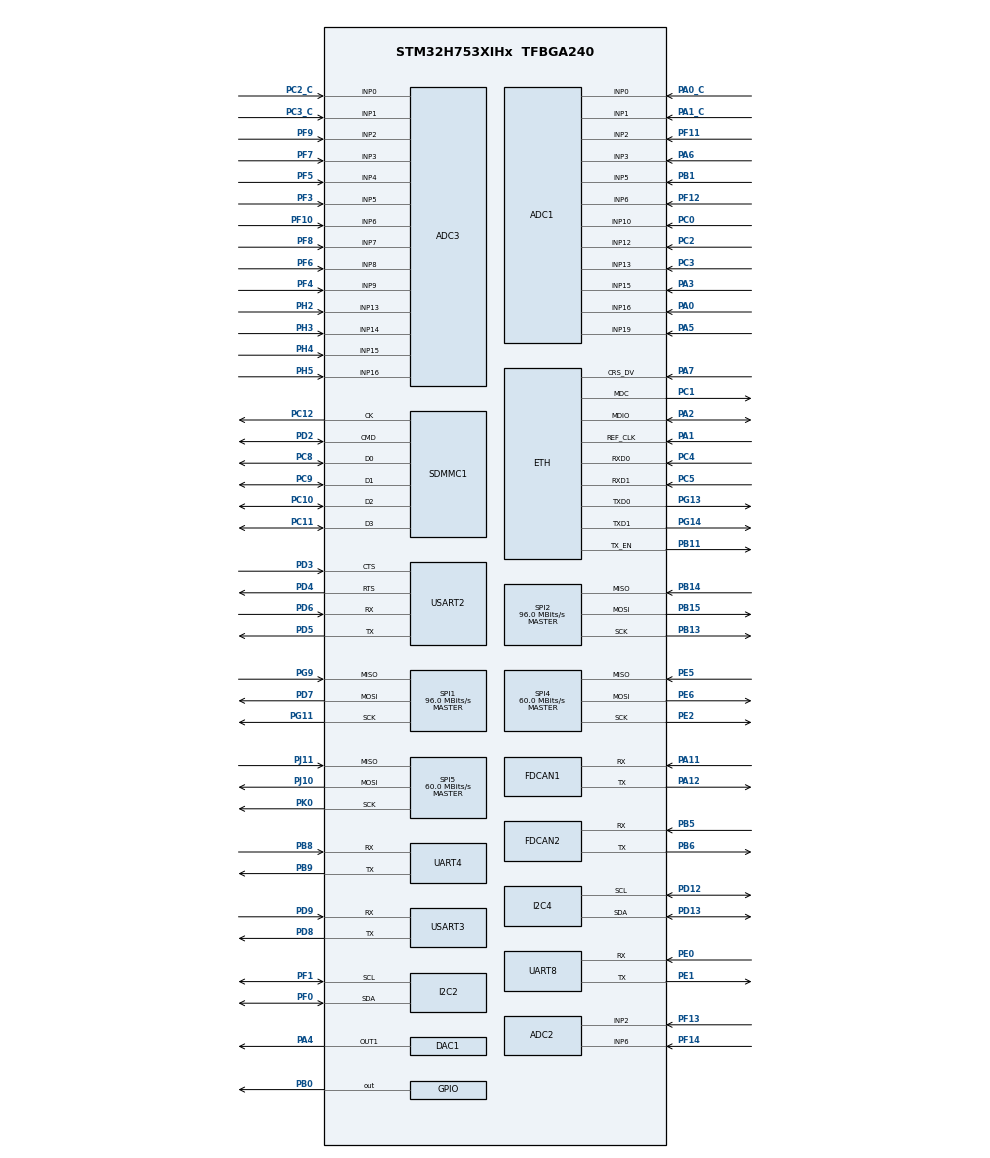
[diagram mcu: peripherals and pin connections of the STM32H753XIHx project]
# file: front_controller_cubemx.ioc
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ADC1.Channel-0\#ChannelRegularConversion=ADC_CHANNEL_1
ADC1.NbrOfConversionFlag=1
ADC1.OffsetNumber-0\#ChannelRegularConversion=ADC_OFFSET_NONE
ADC1.OffsetSignedSaturation-0\#ChannelRegularConversion=DISABLE
ADC1.Rank-0\#ChannelRegularConversion=1
ADC1.SamplingTime-0\#ChannelRegularConversion=ADC_SAMPLETIME_1CYCLE_5
ADC1.master=1
ADC2.Channel-1\#ChannelRegularConversion=ADC_CHANNEL_6
ADC2.NbrOfConversionFlag=1
ADC2.OffsetNumber-1\#ChannelRegularConversion=ADC_OFFSET_NONE
ADC2.OffsetSignedSaturation-1\#ChannelRegularConversion=DISABLE
ADC2.Rank-1\#ChannelRegularConversion=1
ADC2.SamplingTime-1\#ChannelRegularConversion=ADC_SAMPLETIME_1CYCLE_5
ADC3.Channel-2\#ChannelRegularConversion=ADC_CHANNEL_16
ADC3.NbrOfConversionFlag=1
ADC3.OffsetNumber-2\#ChannelRegularConversion=ADC_OFFSET_NONE
ADC3.OffsetSignedSaturation-2\#ChannelRegularConversion=DISABLE
ADC3.Rank-2\#ChannelRegularConversion=1
ADC3.SamplingTime-2\#ChannelRegularConversion=ADC_SAMPLETIME_1CYCLE_5
CORTEX_M7.AccessPermission_S-Cortex_Memory_Protection_Unit_Region2_Settings_S=MPU_REGION_FULL_ACCESS
CORTEX_M7.BaseAddress_S-Cortex_Memory_Protection_Unit_Region2_Settings_S=0x30040000
CORTEX_M7.CPU_DCache=Enabled
CORTEX_M7.CPU_ICache=Enabled
CORTEX_M7.DisableExec_S-Cortex_Memory_Protection_Unit_Region2_Settings_S=MPU_INSTRUCTION_ACCESS_DISABLE
CORTEX_M7.Enable_S-Cortex_Memory_Protection_Unit_Region2_Settings_S=MPU_REGION_ENABLE
CORTEX_M7.IsBufferable_S-Cortex_Memory_Protection_Unit_Region2_Settings_S=MPU_ACCESS_BUFFERABLE
CORTEX_M7.IsShareable_S-Cortex_Memory_Protection_Unit_Region2_Settings_S=MPU_ACCESS_SHAREABLE
CORTEX_M7.Size_S-Cortex_Memory_Protection_Unit_Region2_Settings_S=MPU_REGION_SIZE_512B
CORTEX_M7.default_mode_Activation=1
DAC1.DAC_Channel-DAC_OUT1=DAC_CHANNEL_1
ETH.MediaInterface=HAL_ETH_RMII_MODE
ETH.RxBufferAddress=0x30040200
ETH.RxDescAddress=0x30040000
ETH.TxDescAddress=0x30040100
FDCAN1.CalculateBaudRateNominal=2500000
FDCAN1.CalculateTimeBitNominal=400
FDCAN1.CalculateTimeQuantumNominal=133.33333333333334
FDCAN2.CalculateBaudRateNominal=2500000
FDCAN2.CalculateTimeBitNominal=400
FDCAN2.CalculateTimeQuantumNominal=133.33333333333334
FREERTOS.Tasks01=defaultTask,24,512,StartDefaultTask,Default,NULL,Dynamic,NULL,NULL
FREERTOS.configENABLE_FPU=1
I2C2.Timing=0x307075B1
I2C4.Timing=0x307075B1
Mcu.Family=STM32H7
Mcu.Name=STM32H753XIHx
Mcu.Package=TFBGA240
NVIC.ETH_IRQn=true\:5\:0\:false\:false\:true\:true\:true\:true\:true
NVIC.PriorityGroup=NVIC_PRIORITYGROUP_4
NVIC.TIM6_DAC_IRQn=true\:15\:0\:false\:false\:true\:false\:false\:true\:true
NVIC.TimeBase=TIM6_DAC_IRQn
NVIC.TimeBaseIP=TIM6
PA0.Mode=IN16-Single-Ended
PA0.Signal=ADC1_INP16
PA0_C.Signal=ADCx_INP0
PA1.GPIO_Speed=GPIO_SPEED_FREQ_VERY_HIGH
PA1.Mode=RMII
PA1.Signal=ETH_REF_CLK
PA11.Mode=FDCAN_Activate
PA11.Signal=FDCAN1_RX
PA12.Mode=FDCAN_Activate
PA12.Signal=FDCAN1_TX
PA13\ (JTMS/SWDIO).Mode=JTAG_5_pins
PA13\ (JTMS/SWDIO).Signal=DEBUG_JTMS-SWDIO
PA14\ (JTCK/SWCLK).Mode=JTAG_5_pins
PA14\ (JTCK/SWCLK).Signal=DEBUG_JTCK-SWCLK
PA15\ (JTDI).Mode=JTAG_5_pins
PA15\ (JTDI).Signal=DEBUG_JTDI
PA1_C.Signal=ADCx_INP1
PA2.GPIO_Speed=GPIO_SPEED_FREQ_VERY_HIGH
PA2.Mode=RMII
PA2.Signal=ETH_MDIO
PA3.Signal=ADCx_INP15
PA4.Signal=COMP_DAC11_group
PA5.Signal=ADCx_INP19
PA6.Signal=ADCx_INP3
PA7.GPIO_Speed=GPIO_SPEED_FREQ_VERY_HIGH
PA7.Mode=RMII
PA7.Signal=ETH_CRS_DV
PB0.Signal=GPIO_Output
PB1.Signal=ADCx_INP5
PB11.GPIO_Speed=GPIO_SPEED_FREQ_VERY_HIGH
PB11.Mode=RMII
PB11.Signal=ETH_TX_EN
PB13.Mode=Full_Duplex_Master
PB13.Signal=SPI2_SCK
PB14.Mode=Full_Duplex_Master
PB14.Signal=SPI2_MISO
PB15.Mode=Full_Duplex_Master
PB15.Signal=SPI2_MOSI
PB3\ (JTDO/TRACESWO).Mode=JTAG_5_pins
PB3\ (JTDO/TRACESWO).Signal=DEBUG_JTDO-SWO
PB4\ (NJTRST).Mode=JTAG_5_pins
PB4\ (NJTRST).Signal=DEBUG_JTRST
PB5.Mode=FDCAN_Activate
PB5.Signal=FDCAN2_RX
PB6.Mode=FDCAN_Activate
PB6.Signal=FDCAN2_TX
PB8.Mode=Asynchronous
PB8.Signal=UART4_RX
PB9.Mode=Asynchronous
PB9.Signal=UART4_TX
PC0.Signal=ADCx_INP10
PC1.GPIO_Speed=GPIO_SPEED_FREQ_VERY_HIGH
PC1.Mode=RMII
PC1.Signal=ETH_MDC
PC10.Mode=SD_4_bits_Wide_bus
PC10.Signal=SDMMC1_D2
PC11.Mode=SD_4_bits_Wide_bus
PC11.Signal=SDMMC1_D3
PC12.Mode=SD_4_bits_Wide_bus
PC12.Signal=SDMMC1_CK
PC14-OSC32_IN\ (OSC32_IN).Mode=LSE-External-Oscillator
PC14-OSC32_IN\ (OSC32_IN).Signal=RCC_OSC32_IN
PC15-OSC32_OUT\ (OSC32_OUT).Mode=LSE-External-Oscillator
PC15-OSC32_OUT\ (OSC32_OUT).Signal=RCC_OSC32_OUT
PC2.Signal=ADCx_INP12
PC2_C.Mode=IN0-Single-Ended
PC2_C.Signal=ADC3_INP0
PC3.Signal=ADCx_INP13
PC3_C.Mode=IN1-Single-Ended
PC3_C.Signal=ADC3_INP1
PC4.GPIO_Speed=GPIO_SPEED_FREQ_VERY_HIGH
PC4.Mode=RMII
PC4.Signal=ETH_RXD0
PC5.GPIO_Speed=GPIO_SPEED_FREQ_VERY_HIGH
PC5.Mode=RMII
PC5.Signal=ETH_RXD1
PC8.Mode=SD_4_bits_Wide_bus
PC8.Signal=SDMMC1_D0
PC9.Mode=SD_4_bits_Wide_bus
PC9.Signal=SDMMC1_D1
PD12.Mode=I2C
PD12.Signal=I2C4_SCL
PD13.Mode=I2C
PD13.Signal=I2C4_SDA
PD2.Mode=SD_4_bits_Wide_bus
PD2.Signal=SDMMC1_CMD
PD3.Mode=CTS_RTS
PD3.Signal=USART2_CTS
PD4.Mode=CTS_RTS
PD4.Signal=USART2_RTS
PD5.Mode=Asynchronous
PD5.Signal=USART2_TX
PD6.Mode=Asynchronous
PD6.Signal=USART2_RX
PD7.Mode=Full_Duplex_Master
PD7.Signal=SPI1_MOSI
PD8.Mode=Asynchronous
PD8.Signal=USART3_TX
PD9.Mode=Asynchronous
PD9.Signal=USART3_RX
PE0.Mode=Asynchronous
PE0.Signal=UART8_RX
PE1.Mode=Asynchronous
PE1.Signal=UART8_TX
PE2.Mode=Full_Duplex_Master
PE2.Signal=SPI4_SCK
PE5.Mode=Full_Duplex_Master
PE5.Signal=SPI4_MISO
PE6.Mode=Full_Duplex_Master
PE6.Signal=SPI4_MOSI
PF0.Mode=I2C
PF0.Signal=I2C2_SDA
PF1.Mode=I2C
PF1.Signal=I2C2_SCL
PF10.Mode=IN6-Single-Ended
PF10.Signal=ADC3_INP6
PF11.Mode=IN2-Single-Ended
PF11.Signal=ADC1_INP2
PF12.Mode=IN6-Single-Ended
PF12.Signal=ADC1_INP6
PF13.Mode=IN2-Single-Ended
PF13.Signal=ADC2_INP2
PF14.Mode=IN6-Single-Ended
PF14.Signal=ADC2_INP6
PF3.Mode=IN5-Single-Ended
PF3.Signal=ADC3_INP5
PF4.Mode=IN9-Single-Ended
PF4.Signal=ADC3_INP9
PF5.Mode=IN4-Single-Ended
PF5.Signal=ADC3_INP4
PF6.Mode=IN8-Single-Ended
PF6.Signal=ADC3_INP8
PF7.Mode=IN3-Single-Ended
PF7.Signal=ADC3_INP3
PF8.Mode=IN7-Single-Ended
PF8.Signal=ADC3_INP7
PF9.Mode=IN2-Single-Ended
PF9.Signal=ADC3_INP2
PG11.Mode=Full_Duplex_Master
PG11.Signal=SPI1_SCK
PG13.GPIO_Speed=GPIO_SPEED_FREQ_VERY_HIGH
PG13.Mode=RMII
PG13.Signal=ETH_TXD0
PG14.GPIO_Speed=GPIO_SPEED_FREQ_VERY_HIGH
PG14.Mode=RMII
PG14.Signal=ETH_TXD1
PG8.GPIO_Speed=GPIO_SPEED_FREQ_VERY_HIGH
PG8.Signal=ETH_PPS_OUT
PG9.Mode=Full_Duplex_Master
PG9.Signal=SPI1_MISO
PH2.Mode=IN13-Single-Ended
PH2.Signal=ADC3_INP13
PH3.Mode=IN14-Single-Ended
PH3.Signal=ADC3_INP14
PH4.Mode=IN15-Single-Ended
PH4.Signal=ADC3_INP15
PH5.Mode=IN16-Single-Ended
PH5.Signal=ADC3_INP16
PJ10.Mode=Full_Duplex_Master
PJ10.Signal=SPI5_MOSI
PJ11.Mode=Full_Duplex_Master
PJ11.Signal=SPI5_MISO
PK0.Mode=Full_Duplex_Master
PK0.Signal=SPI5_SCK
PWR.PVDLevel=PWR_PVDLEVEL_5
ProjectManager.HeapSize=0x2000
ProjectManager.StackSize=0x400
ProjectManager.TargetToolchain=CMake
RCC.ADCFreq_Value=80000000
RCC.APB1Freq_Value=120000000
RCC.APB2Freq_Value=120000000
RCC.APB3Freq_Value=120000000
RCC.APB4Freq_Value=120000000
RCC.CortexFreq_Value=480000000
RCC.D1PPRE=RCC_APB3_DIV2
RCC.D2PPRE1=RCC_APB1_DIV2
RCC.D2PPRE2=RCC_APB2_DIV2
RCC.D3PPRE=RCC_APB4_DIV2
RCC.DIVM1=4
RCC.DIVM2=4
RCC.DIVM3=16
RCC.DIVN1=60
RCC.DIVN2=15
RCC.DIVN3=30
RCC.DIVP2=3
RCC.DIVQ1=5
RCC.DIVQ3=4
RCC.DIVR1=6
RCC.DIVR2=3
RCC.FDCANCLockSelection=RCC_FDCANCLKSOURCE_PLL2
RCC.HCLKFreq_Value=240000000
RCC.HPRE=RCC_HCLK_DIV2
RCC.PLL2FRACN=0
RCC.PLL3FRACN=0
RCC.PLLFRACN=0
RCC.PLLSourceVirtual=RCC_PLLSOURCE_HSI
RCC.RTCClockSelection=RCC_RTCCLKSOURCE_LSE
RCC.SYSCLKFreq_VALUE=480000000
RCC.SYSCLKSource=RCC_SYSCLKSOURCE_PLLCLK
RCC.USBCLockSelection=RCC_USBCLKSOURCE_HSI48
RCC.USBFreq_Value=48000000
SH.ADCx_INP0.0=ADC1_INP0,IN0-Single-Ended
SH.ADCx_INP1.0=ADC1_INP1,IN1-Single-Ended
SH.ADCx_INP10.0=ADC1_INP10,IN10-Single-Ended
SH.ADCx_INP12.0=ADC1_INP12,IN12-Single-Ended
SH.ADCx_INP13.0=ADC1_INP13,IN13-Single-Ended
SH.ADCx_INP15.0=ADC1_INP15,IN15-Single-Ended
SH.ADCx_INP19.0=ADC1_INP19,IN19-Single-Ended
SH.ADCx_INP3.0=ADC1_INP3,IN3-Single-Ended
SH.ADCx_INP5.0=ADC1_INP5,IN5-Single-Ended
SH.COMP_DAC11_group.0=DAC1_OUT1,DAC_OUT1
SPI1.BaudRatePrescaler=SPI_BAUDRATEPRESCALER_2
SPI1.CalculateBaudRate=96.0 MBits/s
SPI1.Direction=SPI_DIRECTION_2LINES
SPI1.Mode=SPI_MODE_MASTER
SPI1.VirtualType=VM_MASTER
SPI2.BaudRatePrescaler=SPI_BAUDRATEPRESCALER_2
SPI2.CalculateBaudRate=96.0 MBits/s
SPI2.Direction=SPI_DIRECTION_2LINES
SPI2.Mode=SPI_MODE_MASTER
SPI2.VirtualType=VM_MASTER
SPI4.BaudRatePrescaler=SPI_BAUDRATEPRESCALER_2
SPI4.CalculateBaudRate=60.0 MBits/s
SPI4.Direction=SPI_DIRECTION_2LINES
SPI4.Mode=SPI_MODE_MASTER
SPI4.VirtualType=VM_MASTER
SPI5.CalculateBaudRate=60.0 MBits/s
SPI5.Direction=SPI_DIRECTION_2LINES
SPI5.Mode=SPI_MODE_MASTER
SPI5.VirtualType=VM_MASTER
USART2.VirtualMode-Asynchronous=VM_ASYNC
USART3.VirtualMode-Asynchronous=VM_ASYNC
VP_FREERTOS_VS_CMSIS_V2.Mode=CMSIS_V2
VP_MEMORYMAP_VS_MEMORYMAP.Mode=CurAppReg
VP_PWR_V_PVD_IN.Mode=Mode_PVD_Int
VP_RNG_VS_RNG.Mode=RNG_Activate
VP_RTC_VS_RTC_Activate.Mode=RTC_Enabled
VP_RTC_VS_RTC_Calendar.Mode=RTC_Calendar
VP_SYS_VS_tim6.Mode=TIM6
VP_VREFBUF_V_VREFBUF.Mode=ExternalMode
board=custom

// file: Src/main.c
/* USER CODE BEGIN Header */
/**
  ******************************************************************************
  * @file           : main.c
  * @brief          : Main program body
  ******************************************************************************
  * @attention
  *
  * Copyright (c) 2025 STMicroelectronics.
  * All rights reserved.
  *
  * This software is licensed under terms that can be found in the LICENSE file
  * in the root directory of this software component.
  * If no LICENSE file comes with this software, it is provided AS-IS.
  *
  ******************************************************************************
  */
/* USER CODE END Header */
#include "main.h"
#include "cmsis_os.h"
#include "adc.h"
#include "dac.h"
#include "eth.h"
#include "fdcan.h"
#include "i2c.h"
#include "rng.h"
#include "rtc.h"
#include "sdmmc.h"
#include "spi.h"
#include "usart.h"
#include "gpio.h"

void SystemClock_Config(void);
void PeriphCommonClock_Config(void);
static void MPU_Config(void);
void MX_FREERTOS_Init(void);
/* USER CODE BEGIN PFP */
#define PUTCHAR_PROTOTYPE int __io_putchar(int ch)
/* USER CODE END PFP */

int main(void)
{

  /* MPU Configuration--------------------------------------------------------*/
  MPU_Config();

  /* Enable the CPU Cache */

  /* Enable I-Cache---------------------------------------------------------*/
  SCB_EnableICache();

  /* Enable D-Cache---------------------------------------------------------*/
  SCB_EnableDCache();

  /* MCU Configuration--------------------------------------------------------*/

  /* Reset of all peripherals, Initializes the Flash interface and the Systick. */
  HAL_Init();

  /* Configure the system clock */
  SystemClock_Config();

  /* Configure the peripherals common clocks */
  PeriphCommonClock_Config();

  /* Initialize all configured peripherals */
  MX_GPIO_Init();
  MX_FDCAN1_Init();
  MX_FDCAN2_Init();
  MX_SDMMC1_SD_Init();
  MX_SPI1_Init();
  MX_SPI2_Init();
  MX_USART2_UART_Init();
  MX_USART3_UART_Init();
  MX_I2C2_Init();
  MX_SPI4_Init();
  MX_RTC_Init();
  MX_RNG_Init();
  MX_DAC1_Init();
  MX_ADC1_Init();
  MX_ADC2_Init();
  MX_ADC3_Init();
  MX_ETH_Init();
  MX_I2C4_Init();
  MX_SPI5_Init();
  MX_UART4_Init();
  MX_UART8_Init();

  /* Init scheduler */
  osKernelInitialize();  /* Call init function for freertos objects (in cmsis_os2.c) */
  MX_FREERTOS_Init();

  /* Start scheduler */
  osKernelStart();

  /* We should never get here as control is now taken by the scheduler */

  /* Infinite loop */
  while (1)
  {

  }
}

void SystemClock_Config(void)
{
  RCC_OscInitTypeDef RCC_OscInitStruct = {0};
  RCC_ClkInitTypeDef RCC_ClkInitStruct = {0};

  /** Supply configuration update enable
  */
  HAL_PWREx_ConfigSupply(PWR_LDO_SUPPLY);

  /** Configure the main internal regulator output voltage
  */
  __HAL_PWR_VOLTAGESCALING_CONFIG(PWR_REGULATOR_VOLTAGE_SCALE0);

  while(!__HAL_PWR_GET_FLAG(PWR_FLAG_VOSRDY)) {}

  /** Configure LSE Drive Capability
  */
  HAL_PWR_EnableBkUpAccess();
  __HAL_RCC_LSEDRIVE_CONFIG(RCC_LSEDRIVE_LOW);

  /** Initializes the RCC Oscillators according to the specified parameters
  * in the RCC_OscInitTypeDef structure.
  */
  RCC_OscInitStruct.OscillatorType = RCC_OSCILLATORTYPE_HSI48|RCC_OSCILLATORTYPE_HSI
                              |RCC_OSCILLATORTYPE_LSE;
  RCC_OscInitStruct.LSEState = RCC_LSE_ON;
  RCC_OscInitStruct.HSIState = RCC_HSI_DIV1;
  RCC_OscInitStruct.HSICalibrationValue = RCC_HSICALIBRATION_DEFAULT;
  RCC_OscInitStruct.HSI48State = RCC_HSI48_ON;
  RCC_OscInitStruct.PLL.PLLState = RCC_PLL_ON;
  RCC_OscInitStruct.PLL.PLLSource = RCC_PLLSOURCE_HSI;
  RCC_OscInitStruct.PLL.PLLM = 4;
  RCC_OscInitStruct.PLL.PLLN = 60;
  RCC_OscInitStruct.PLL.PLLP = 2;
  RCC_OscInitStruct.PLL.PLLQ = 5;
  RCC_OscInitStruct.PLL.PLLR = 6;
  RCC_OscInitStruct.PLL.PLLRGE = RCC_PLL1VCIRANGE_3;
  RCC_OscInitStruct.PLL.PLLVCOSEL = RCC_PLL1VCOWIDE;
  RCC_OscInitStruct.PLL.PLLFRACN = 0;
  if (HAL_RCC_OscConfig(&RCC_OscInitStruct) != HAL_OK)
  {
    Error_Handler();
  }

  /** Initializes the CPU, AHB and APB buses clocks
  */
  RCC_ClkInitStruct.ClockType = RCC_CLOCKTYPE_HCLK|RCC_CLOCKTYPE_SYSCLK
                              |RCC_CLOCKTYPE_PCLK1|RCC_CLOCKTYPE_PCLK2
                              |RCC_CLOCKTYPE_D3PCLK1|RCC_CLOCKTYPE_D1PCLK1;
  RCC_ClkInitStruct.SYSCLKSource = RCC_SYSCLKSOURCE_PLLCLK;
  RCC_ClkInitStruct.SYSCLKDivider = RCC_SYSCLK_DIV1;
  RCC_ClkInitStruct.AHBCLKDivider = RCC_HCLK_DIV2;
  RCC_ClkInitStruct.APB3CLKDivider = RCC_APB3_DIV2;
  RCC_ClkInitStruct.APB1CLKDivider = RCC_APB1_DIV2;
  RCC_ClkInitStruct.APB2CLKDivider = RCC_APB2_DIV2;
  RCC_ClkInitStruct.APB4CLKDivider = RCC_APB4_DIV2;

  if (HAL_RCC_ClockConfig(&RCC_ClkInitStruct, FLASH_LATENCY_4) != HAL_OK)
  {
    Error_Handler();
  }
}

void PeriphCommonClock_Config(void)
{
  RCC_PeriphCLKInitTypeDef PeriphClkInitStruct = {0};

  /** Initializes the peripherals clock
  */
  PeriphClkInitStruct.PeriphClockSelection = RCC_PERIPHCLK_ADC|RCC_PERIPHCLK_FDCAN;
  PeriphClkInitStruct.PLL2.PLL2M = 4;
  PeriphClkInitStruct.PLL2.PLL2N = 15;
  PeriphClkInitStruct.PLL2.PLL2P = 3;
  PeriphClkInitStruct.PLL2.PLL2Q = 2;
  PeriphClkInitStruct.PLL2.PLL2R = 3;
  PeriphClkInitStruct.PLL2.PLL2RGE = RCC_PLL2VCIRANGE_3;
  PeriphClkInitStruct.PLL2.PLL2VCOSEL = RCC_PLL2VCOWIDE;
  PeriphClkInitStruct.PLL2.PLL2FRACN = 0;
  PeriphClkInitStruct.FdcanClockSelection = RCC_FDCANCLKSOURCE_PLL2;
  PeriphClkInitStruct.AdcClockSelection = RCC_ADCCLKSOURCE_PLL2;
  if (HAL_RCCEx_PeriphCLKConfig(&PeriphClkInitStruct) != HAL_OK)
  {
    Error_Handler();
  }
}

/* USER CODE BEGIN 4 */

PUTCHAR_PROTOTYPE
{
  /* Place your implementation of fputc here */
  /* e.g. write a character to the USART1 and Loop until the end of transmission */
  HAL_UART_Transmit(&huart3, (uint8_t *)&ch, 1, 0xFFFF);

  return ch;
}

/* USER CODE END 4 */

 /* MPU Configuration */

void MPU_Config(void)
{
  MPU_Region_InitTypeDef MPU_InitStruct = {0};

  /* Disables the MPU */
  HAL_MPU_Disable();

  /** Initializes and configures the Region and the memory to be protected
  */
  MPU_InitStruct.Enable = MPU_REGION_ENABLE;
  MPU_InitStruct.Number = MPU_REGION_NUMBER0;
  MPU_InitStruct.BaseAddress = 0x0;
  MPU_InitStruct.Size = MPU_REGION_SIZE_4GB;
  MPU_InitStruct.SubRegionDisable = 0x87;
  MPU_InitStruct.TypeExtField = MPU_TEX_LEVEL0;
  MPU_InitStruct.AccessPermission = MPU_REGION_NO_ACCESS;
  MPU_InitStruct.DisableExec = MPU_INSTRUCTION_ACCESS_DISABLE;
  MPU_InitStruct.IsShareable = MPU_ACCESS_SHAREABLE;
  MPU_InitStruct.IsCacheable = MPU_ACCESS_NOT_CACHEABLE;
  MPU_InitStruct.IsBufferable = MPU_ACCESS_NOT_BUFFERABLE;

  HAL_MPU_ConfigRegion(&MPU_InitStruct);

  /** Initializes and configures the Region and the memory to be protected
  */
  MPU_InitStruct.Number = MPU_REGION_NUMBER2;
  MPU_InitStruct.BaseAddress = 0x30040000;
  MPU_InitStruct.Size = MPU_REGION_SIZE_512B;
  MPU_InitStruct.SubRegionDisable = 0x0;
  MPU_InitStruct.AccessPermission = MPU_REGION_FULL_ACCESS;
  MPU_InitStruct.IsBufferable = MPU_ACCESS_BUFFERABLE;

  HAL_MPU_ConfigRegion(&MPU_InitStruct);
  /* Enables the MPU */
  HAL_MPU_Enable(MPU_PRIVILEGED_DEFAULT);

}

void HAL_TIM_PeriodElapsedCallback(TIM_HandleTypeDef *htim)
{
  if (htim->Instance == TIM6)
  {
    HAL_IncTick();
  }
}

void Error_Handler(void)
{
  __disable_irq();
  while (1)
  {
  }
}

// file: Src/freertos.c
/* USER CODE BEGIN Header */
/**
  ******************************************************************************
  * File Name          : freertos.c
  * Description        : Code for freertos applications
  ******************************************************************************
  * @attention
  *
  * Copyright (c) 2025 STMicroelectronics.
  * All rights reserved.
  *
  * This software is licensed under terms that can be found in the LICENSE file
  * in the root directory of this software component.
  * If no LICENSE file comes with this software, it is provided AS-IS.
  *
  ******************************************************************************
  */
/* USER CODE END Header */

#include "FreeRTOS.h"
#include "task.h"
#include "main.h"
#include "cmsis_os.h"

/* USER CODE BEGIN Includes */
#include "eth.h"
#include <stdio.h>
/* USER CODE END Includes */

/* Definitions for defaultTask */
osThreadId_t defaultTaskHandle;
const osThreadAttr_t defaultTask_attributes = {
  .name = "defaultTask",
  .stack_size = 512 * 4,
  .priority = (osPriority_t) osPriorityNormal,
};

void StartDefaultTask(void *argument);

void MX_FREERTOS_Init(void); /* (MISRA C 2004 rule 8.1) */

void MX_FREERTOS_Init(void) {

  /* Create the thread(s) */
  /* creation of defaultTask */
  defaultTaskHandle = osThreadNew(StartDefaultTask, NULL, &defaultTask_attributes);

}

void StartDefaultTask(void *argument)
{
  /* USER CODE BEGIN StartDefaultTask */
  /* Infinite loop */
  for(;;)
  {
    osDelay(250);
    HAL_GPIO_TogglePin(GPIOB, GPIO_PIN_0);
    printf("swag\r\n");
    //HAL_ETH_Transmit(&heth, ETH_TxPacketConfigTypeDef *pTxConfig, 0);
    //HAL_ETH_ReleaseTxPacket(ETH_HandleTypeDef *heth)
  }
  /* USER CODE END StartDefaultTask */
}
